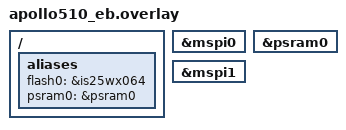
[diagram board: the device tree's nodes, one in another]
/*
 * Copyright (c) 2025, Ambiq Micro Inc. <www.ambiq.com>
 *
 * SPDX-License-Identifier: Apache-2.0
 */

/ {
	aliases {
		flash0 = &is25wx064;
		psram0 = &psram0;
	};
};

&mspi0 {
	/delete-property/ zephyr,pm-device-runtime-auto;
};

&psram0 {
	/delete-property/ zephyr,pm-device-runtime-auto;
};

&mspi1 {
	/delete-property/ zephyr,pm-device-runtime-auto;
};
